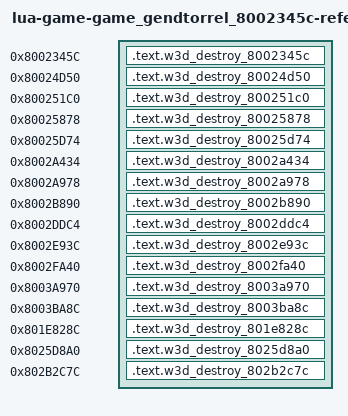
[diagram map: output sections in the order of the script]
/* Generated reference-only placements. All bodies are source-built. */
OUTPUT_FORMAT("elf32-powerpc")
OUTPUT_ARCH(powerpc)
ENTRY(w3d_destroy_8002345c)
_SDA_BASE_ = 0x804b2540;
_SDA2_BASE_ = 0x804c2540;
fn_8002a978 = 0x8002a978;
fn_8015ff2c = 0x8015ff2c;
fn_80161050 = 0x80161050;
fn_801628ec = 0x801628ec;
fn_80210990 = 0x80210990;
lbl_8040de88 = 0x8040de88;
lbl_8040dec8 = 0x8040dec8;
lbl_8040df08 = 0x8040df08;
lbl_8040df48 = 0x8040df48;
lbl_8040dfc8 = 0x8040dfc8;
lbl_8040e2c8 = 0x8040e2c8;
lbl_8040e310 = 0x8040e310;
lbl_8040e3a8 = 0x8040e3a8;
lbl_8040e478 = 0x8040e478;
lbl_8040e4b8 = 0x8040e4b8;
lbl_8040e4f8 = 0x8040e4f8;
lbl_8040e718 = 0x8040e718;
lbl_8040e758 = 0x8040e758;
lbl_8041baf0 = 0x8041baf0;
lbl_8041c670 = 0x8041c670;
SECTIONS {
  .text.w3d_destroy_8002345c 0x8002345c : { *(.text.w3d_destroy_8002345c) }
  .text.w3d_destroy_80024d50 0x80024d50 : { *(.text.w3d_destroy_80024d50) }
  .text.w3d_destroy_800251c0 0x800251c0 : { *(.text.w3d_destroy_800251c0) }
  .text.w3d_destroy_80025878 0x80025878 : { *(.text.w3d_destroy_80025878) }
  .text.w3d_destroy_80025d74 0x80025d74 : { *(.text.w3d_destroy_80025d74) }
  .text.w3d_destroy_8002a434 0x8002a434 : { *(.text.w3d_destroy_8002a434) }
  .text.w3d_destroy_8002a978 0x8002a978 : { *(.text.w3d_destroy_8002a978) }
  .text.w3d_destroy_8002b890 0x8002b890 : { *(.text.w3d_destroy_8002b890) }
  .text.w3d_destroy_8002ddc4 0x8002ddc4 : { *(.text.w3d_destroy_8002ddc4) }
  .text.w3d_destroy_8002e93c 0x8002e93c : { *(.text.w3d_destroy_8002e93c) }
  .text.w3d_destroy_8002fa40 0x8002fa40 : { *(.text.w3d_destroy_8002fa40) }
  .text.w3d_destroy_8003a970 0x8003a970 : { *(.text.w3d_destroy_8003a970) }
  .text.w3d_destroy_8003ba8c 0x8003ba8c : { *(.text.w3d_destroy_8003ba8c) }
  .text.w3d_destroy_801e828c 0x801e828c : { *(.text.w3d_destroy_801e828c) }
  .text.w3d_destroy_8025d8a0 0x8025d8a0 : { *(.text.w3d_destroy_8025d8a0) }
  .text.w3d_destroy_802b2c7c 0x802b2c7c : { *(.text.w3d_destroy_802b2c7c) }
  /DISCARD/ : { *(.text*) *(.rodata*) *(.data*) *(.bss*) *(.sdata*) *(.sbss*) *(.comment) }
}
